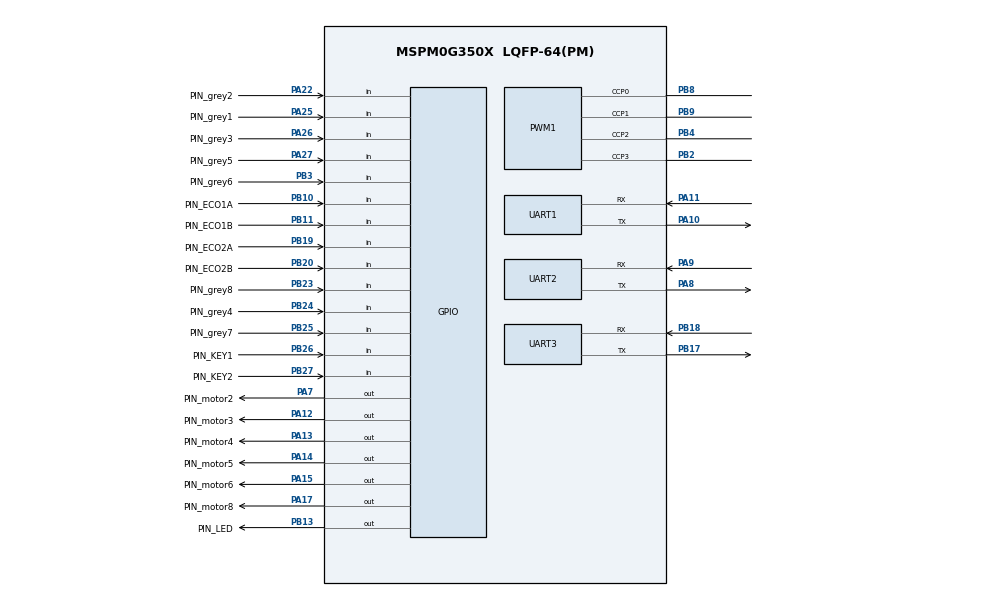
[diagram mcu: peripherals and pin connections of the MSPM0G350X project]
/**
 * @cliArgs --device "MSPM0G350X" --package "LQFP-64(PM)" --part "Default" --product "mspm0_sdk@2.01.00.03"
 * @versions {"tool":"1.20.0+3587"}
 */

/**
 * Import the modules used in this configuration.
 */
const GPIO   = scripting.addModule("/ti/driverlib/GPIO", {}, false);
const GPIO1  = GPIO.addInstance();
const GPIO2  = GPIO.addInstance();
const GPIO3  = GPIO.addInstance();
const GPIO4  = GPIO.addInstance();
const GPIO5  = GPIO.addInstance();
const GPIO6  = GPIO.addInstance();
const GPIO7  = GPIO.addInstance();
const PWM    = scripting.addModule("/ti/driverlib/PWM", {}, false);
const PWM1   = PWM.addInstance();
const SYSCTL = scripting.addModule("/ti/driverlib/SYSCTL");
const TIMER  = scripting.addModule("/ti/driverlib/TIMER", {}, false);
const TIMER1 = TIMER.addInstance();
const TIMER2 = TIMER.addInstance();
const UART   = scripting.addModule("/ti/driverlib/UART", {}, false);
const UART1  = UART.addInstance();
const UART2  = UART.addInstance();
const UART3  = UART.addInstance();

/**
 * Write custom configuration values to the imported modules.
 */
const divider6       = system.clockTree["PLL_CLK2X_DIV"];
divider6.divideValue = 4;

const divider7       = system.clockTree["PLL_PDIV"];
divider7.divideValue = 2;

const divider9       = system.clockTree["UDIV"];
divider9.divideValue = 2;

const multiplier2         = system.clockTree["PLL_QDIV"];
multiplier2.multiplyValue = 10;

const mux8       = system.clockTree["HSCLKMUX"];
mux8.inputSelect = "HSCLKMUX_SYSPLL2X";

GPIO1.$name                         = "GPIO_LED";
GPIO1.port                          = "PORTB";
GPIO1.associatedPins[0].$name       = "PIN_LED";
GPIO1.associatedPins[0].assignedPin = "13";
GPIO1.associatedPins[0].pin.$assign = "PB13";

const Board = scripting.addModule("/ti/driverlib/Board", {}, false);

GPIO2.$name                          = "GPIO_MOTOR";
GPIO2.associatedPins.create(8);
GPIO2.associatedPins[0].assignedPort = "PORTA";
GPIO2.associatedPins[0].assignedPin  = "1";
GPIO2.associatedPins[0].$name        = "PIN_motor1";
GPIO2.associatedPins[1].$name        = "PIN_motor2";
GPIO2.associatedPins[1].assignedPort = "PORTA";
GPIO2.associatedPins[1].assignedPin  = "7";
GPIO2.associatedPins[1].pin.$assign  = "PA7";
GPIO2.associatedPins[2].$name        = "PIN_motor3";
GPIO2.associatedPins[2].assignedPin  = "12";
GPIO2.associatedPins[2].pin.$assign  = "PA12";
GPIO2.associatedPins[3].$name        = "PIN_motor4";
GPIO2.associatedPins[3].assignedPort = "PORTA";
GPIO2.associatedPins[3].assignedPin  = "13";
GPIO2.associatedPins[3].pin.$assign  = "PA13";
GPIO2.associatedPins[4].$name        = "PIN_motor5";
GPIO2.associatedPins[4].assignedPort = "PORTA";
GPIO2.associatedPins[4].assignedPin  = "14";
GPIO2.associatedPins[4].pin.$assign  = "PA14";
GPIO2.associatedPins[5].$name        = "PIN_motor6";
GPIO2.associatedPins[5].assignedPort = "PORTA";
GPIO2.associatedPins[5].assignedPin  = "15";
GPIO2.associatedPins[5].pin.$assign  = "PA15";
GPIO2.associatedPins[6].$name        = "PIN_motor7";
GPIO2.associatedPins[6].assignedPort = "PORTA";
GPIO2.associatedPins[6].assignedPin  = "16";
GPIO2.associatedPins[7].$name        = "PIN_motor8";
GPIO2.associatedPins[7].assignedPort = "PORTA";
GPIO2.associatedPins[7].assignedPin  = "17";
GPIO2.associatedPins[7].pin.$assign  = "PA17";

GPIO3.$name                          = "GPIO_OLED";
GPIO3.associatedPins.create(2);
GPIO3.associatedPins[0].assignedPort = "PORTA";
GPIO3.associatedPins[0].assignedPin  = "28";
GPIO3.associatedPins[0].$name        = "PIN_SCL";
GPIO3.associatedPins[1].assignedPort = "PORTA";
GPIO3.associatedPins[1].assignedPin  = "31";
GPIO3.associatedPins[1].$name        = "PIN_SDA";

GPIO4.$name                         = "GPIO_BUZZER";
GPIO4.port                          = "PORTB";
GPIO4.associatedPins[0].$name       = "PIN_buzzer";
GPIO4.associatedPins[0].assignedPin = "0";

GPIO5.$name                         = "GPIO_ENCONDER";
GPIO5.associatedPins.create(4);
GPIO5.associatedPins[0].$name       = "PIN_ECO1A";
GPIO5.associatedPins[0].direction   = "INPUT";
GPIO5.associatedPins[0].polarity    = "RISE";
GPIO5.associatedPins[0].interruptEn = true;
GPIO5.associatedPins[0].pin.$assign = "PB10";
GPIO5.associatedPins[1].$name       = "PIN_ECO1B";
GPIO5.associatedPins[1].direction   = "INPUT";
GPIO5.associatedPins[1].pin.$assign = "PB11";
GPIO5.associatedPins[2].$name       = "PIN_ECO2A";
GPIO5.associatedPins[2].direction   = "INPUT";
GPIO5.associatedPins[2].interruptEn = true;
GPIO5.associatedPins[2].polarity    = "RISE";
GPIO5.associatedPins[2].pin.$assign = "PB19";
GPIO5.associatedPins[3].$name       = "PIN_ECO2B";
GPIO5.associatedPins[3].direction   = "INPUT";
GPIO5.associatedPins[3].pin.$assign = "PB20";

GPIO6.$name                         = "GPIO_huidu";
GPIO6.associatedPins.create(8);
GPIO6.associatedPins[0].direction   = "INPUT";
GPIO6.associatedPins[0].$name       = "PIN_grey1";
GPIO6.associatedPins[0].pin.$assign = "PA25";
GPIO6.associatedPins[1].direction   = "INPUT";
GPIO6.associatedPins[1].$name       = "PIN_grey2";
GPIO6.associatedPins[1].pin.$assign = "PA22";
GPIO6.associatedPins[2].direction   = "INPUT";
GPIO6.associatedPins[2].$name       = "PIN_grey3";
GPIO6.associatedPins[2].pin.$assign = "PA26";
GPIO6.associatedPins[3].direction   = "INPUT";
GPIO6.associatedPins[3].$name       = "PIN_grey4";
GPIO6.associatedPins[3].pin.$assign = "PB24";
GPIO6.associatedPins[4].direction   = "INPUT";
GPIO6.associatedPins[4].$name       = "PIN_grey5";
GPIO6.associatedPins[4].pin.$assign = "PA27";
GPIO6.associatedPins[5].direction   = "INPUT";
GPIO6.associatedPins[5].$name       = "PIN_grey6";
GPIO6.associatedPins[5].pin.$assign = "PB3";
GPIO6.associatedPins[6].$name       = "PIN_grey7";
GPIO6.associatedPins[6].direction   = "INPUT";
GPIO6.associatedPins[6].pin.$assign = "PB25";
GPIO6.associatedPins[7].$name       = "PIN_grey8";
GPIO6.associatedPins[7].direction   = "INPUT";
GPIO6.associatedPins[7].pin.$assign = "PB23";

GPIO7.$name                              = "GPIO_KEY";
GPIO7.associatedPins.create(2);
GPIO7.associatedPins[0].direction        = "INPUT";
GPIO7.associatedPins[0].$name            = "PIN_KEY1";
GPIO7.associatedPins[0].internalResistor = "PULL_UP";
GPIO7.associatedPins[0].assignedPort     = "PORTB";
GPIO7.associatedPins[0].assignedPin      = "26";
GPIO7.associatedPins[0].pin.$assign      = "PB26";
GPIO7.associatedPins[1].$name            = "PIN_KEY2";
GPIO7.associatedPins[1].direction        = "INPUT";
GPIO7.associatedPins[1].assignedPort     = "PORTB";
GPIO7.associatedPins[1].internalResistor = "PULL_UP";
GPIO7.associatedPins[1].assignedPin      = "27";
GPIO7.associatedPins[1].pin.$assign      = "PB27";

PWM1.$name                              = "PWM_A0";
PWM1.clockDivider                       = 8;
PWM1.clockPrescale                      = 100;
PWM1.timerCount                         = 100;
PWM1.ccIndex                            = [0,1,2,3];
PWM1.peripheral.$assign                 = "TIMA0";
PWM1.peripheral.ccp0Pin.$assign         = "PB8";
PWM1.peripheral.ccp1Pin.$assign         = "PB9";
PWM1.peripheral.ccp2Pin.$assign         = "PB4";
PWM1.peripheral.ccp3Pin.$assign         = "PB2";
PWM1.PWM_CHANNEL_0.$name                = "ti_driverlib_pwm_PWMTimerCC0";
PWM1.PWM_CHANNEL_0.dutyCycle            = 50;
PWM1.PWM_CHANNEL_1.$name                = "ti_driverlib_pwm_PWMTimerCC1";
PWM1.PWM_CHANNEL_1.dutyCycle            = 50;
PWM1.ccp0PinConfig.direction            = scripting.forceWrite("OUTPUT");
PWM1.ccp0PinConfig.hideOutputInversion  = scripting.forceWrite(false);
PWM1.ccp0PinConfig.onlyInternalResistor = scripting.forceWrite(false);
PWM1.ccp0PinConfig.passedPeripheralType = scripting.forceWrite("Digital");
PWM1.ccp0PinConfig.$name                = "ti_driverlib_gpio_GPIOPinGeneric8";
PWM1.ccp1PinConfig.direction            = scripting.forceWrite("OUTPUT");
PWM1.ccp1PinConfig.hideOutputInversion  = scripting.forceWrite(false);
PWM1.ccp1PinConfig.onlyInternalResistor = scripting.forceWrite(false);
PWM1.ccp1PinConfig.passedPeripheralType = scripting.forceWrite("Digital");
PWM1.ccp1PinConfig.$name                = "ti_driverlib_gpio_GPIOPinGeneric9";
PWM1.PWM_CHANNEL_2.$name                = "ti_driverlib_pwm_PWMTimerCC2";
PWM1.PWM_CHANNEL_2.dutyCycle            = 50;
PWM1.PWM_CHANNEL_3.$name                = "ti_driverlib_pwm_PWMTimerCC3";
PWM1.PWM_CHANNEL_3.dutyCycle            = 50;
PWM1.ccp2PinConfig.$name                = "ti_driverlib_gpio_GPIOPinGeneric10";
PWM1.ccp3PinConfig.$name                = "ti_driverlib_gpio_GPIOPinGeneric11";

SYSCTL.forceDefaultClkConfig = true;
SYSCTL.clockTreeEn           = true;

TIMER1.timerMode          = "PERIODIC";
TIMER1.interrupts         = ["ZERO"];
TIMER1.timerStartTimer    = true;
TIMER1.$name              = "TIMER_G0";
TIMER1.timerClkPrescale   = 100;
TIMER1.timerPeriod        = "5ms";
TIMER1.peripheral.$assign = "TIMG0";

TIMER2.$name              = "TIMER_G6";
TIMER2.timerMode          = "PERIODIC";
TIMER2.timerClkPrescale   = 200;
TIMER2.interrupts         = ["ZERO"];
TIMER2.timerPeriod        = "10ms";
TIMER2.peripheral.$assign = "TIMG6";

UART1.$name                    = "UART_0";
UART1.targetBaudRate           = 115200;
UART1.enabledInterrupts        = ["RX"];
UART1.peripheral.$assign       = "UART0";
UART1.peripheral.rxPin.$assign = "PA11";
UART1.peripheral.txPin.$assign = "PA10";
UART1.txPinConfig.$name        = "ti_driverlib_gpio_GPIOPinGeneric0";
UART1.rxPinConfig.$name        = "ti_driverlib_gpio_GPIOPinGeneric1";

UART2.$name                    = "UART_1";
UART2.enabledInterrupts        = ["RX"];
UART2.peripheral.$assign       = "UART1";
UART2.peripheral.rxPin.$assign = "PA9";
UART2.peripheral.txPin.$assign = "PA8";
UART2.txPinConfig.$name        = "ti_driverlib_gpio_GPIOPinGeneric2";
UART2.rxPinConfig.$name        = "ti_driverlib_gpio_GPIOPinGeneric3";

UART3.$name                    = "UART_2";
UART3.enabledInterrupts        = ["RX"];
UART3.targetBaudRate           = 115200;
UART3.peripheral.$assign       = "UART2";
UART3.peripheral.rxPin.$assign = "PB18";
UART3.peripheral.txPin.$assign = "PB17";
UART3.txPinConfig.$name        = "ti_driverlib_gpio_GPIOPinGeneric4";
UART3.rxPinConfig.$name        = "ti_driverlib_gpio_GPIOPinGeneric5";

/**
 * Pinmux solution for unlocked pins/peripherals. This ensures that minor changes to the automatic solver in a future
 * version of the tool will not impact the pinmux you originally saw.  These lines can be completely deleted in order to
 * re-solve from scratch.
 */
Board.peripheral.$suggestSolution            = "DEBUGSS";
Board.peripheral.swclkPin.$suggestSolution   = "PA20";
Board.peripheral.swdioPin.$suggestSolution   = "PA19";
GPIO2.associatedPins[0].pin.$suggestSolution = "PA1";
GPIO2.associatedPins[6].pin.$suggestSolution = "PA16";
GPIO3.associatedPins[0].pin.$suggestSolution = "PA28";
GPIO3.associatedPins[1].pin.$suggestSolution = "PA31";
GPIO4.associatedPins[0].pin.$suggestSolution = "PB0";
